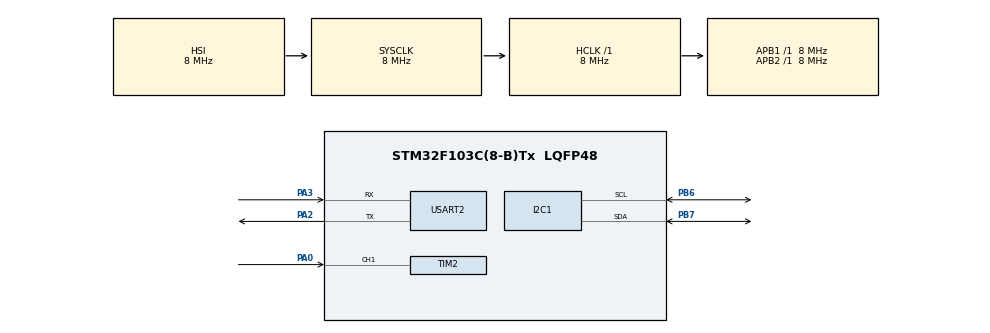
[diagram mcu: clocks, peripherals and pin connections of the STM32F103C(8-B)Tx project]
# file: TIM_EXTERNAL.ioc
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Mcu.Family=STM32F1
Mcu.Name=STM32F103C(8-B)Tx
Mcu.Package=LQFP48
NVIC.PriorityGroup=NVIC_PRIORITYGROUP_4
NVIC.TIM2_IRQn=true\:0\:0\:false\:false\:true\:true\:true\:true
PA0-WKUP.Signal=S_TIM2_CH1_ETR
PA13.Mode=Serial_Wire
PA13.Signal=SYS_JTMS-SWDIO
PA14.Mode=Serial_Wire
PA14.Signal=SYS_JTCK-SWCLK
PA2.Mode=Asynchronous
PA2.Signal=USART2_TX
PA3.Mode=Asynchronous
PA3.Signal=USART2_RX
PB6.Mode=I2C
PB6.Signal=I2C1_SCL
PB7.Mode=I2C
PB7.Signal=I2C1_SDA
ProjectManager.HeapSize=0x200
ProjectManager.StackSize=0x400
ProjectManager.TargetToolchain=STM32CubeIDE
RCC.AHBFreq_Value=8000000
RCC.APB1Freq_Value=8000000
RCC.APB1TimFreq_Value=8000000
RCC.APB2Freq_Value=8000000
RCC.APB2TimFreq_Value=8000000
RCC.HCLKFreq_Value=8000000
RCC.SYSCLKFreq_VALUE=8000000
RCC.USBFreq_Value=8000000
SH.S_TIM2_CH1_ETR.0=TIM2_CH1,TriggerSource_TI1FP1
TIM2.Period=5000-1
TIM2.Prescaler=8000-1
TIM2.Slave_TriggerFilter=15
USART2.VirtualMode=VM_ASYNC
VP_TIM2_VS_ClockSourceINT.Mode=Internal
VP_TIM2_VS_ControllerModeReset.Mode=Reset Mode
board=custom

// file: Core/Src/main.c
/* USER CODE BEGIN Header */
/**
  ******************************************************************************
  * @file           : main.c
  * @brief          : Main program body
  ******************************************************************************
  * @attention
  *
  * Copyright (c) 2024 STMicroelectronics.
  * All rights reserved.
  *
  * This software is licensed under terms that can be found in the LICENSE file
  * in the root directory of this software component.
  * If no LICENSE file comes with this software, it is provided AS-IS.
  *
  ******************************************************************************
  */
/* USER CODE END Header */
#include "main.h"
#include "i2c.h"
#include "tim.h"
#include "usart.h"
#include "gpio.h"

/* USER CODE BEGIN Includes */
#include "oled.h"
#include "stdio.h"
#include "string.h"
/* USER CODE END Includes */

void SystemClock_Config(void);

/* USER CODE BEGIN 0 */
char updataMsg[]="自动重载😊😊😊";
void HAL_TIM_PeriodElapsedCallback(TIM_HandleTypeDef *htim)
{
  if (htim == &htim2)
  {
    HAL_UART_Transmit(&huart2, (uint8_t *)updataMsg, strlen(updataMsg), 100);
  }
}
/* USER CODE END 0 */

int main(void)
{

  /* MCU Configuration--------------------------------------------------------*/

  /* Reset of all peripherals, Initializes the Flash interface and the Systick. */
  HAL_Init();

  /* Configure the system clock */
  SystemClock_Config();

  /* Initialize all configured peripherals */
  MX_GPIO_Init();
  MX_I2C1_Init();
  MX_TIM2_Init();
  MX_USART2_UART_Init();
  /* USER CODE BEGIN 2 */

  HAL_TIM_Base_Start(&htim2);
  int counter = 0;
  char str[20] = "";
  /* USER CODE END 2 */

  /* Infinite loop */
  /* USER CODE BEGIN WHILE */
  while (1)
  {
    //OLED_NewFrame();
    counter = __HAL_TIM_GET_COUNTER(&htim2);
    sprintf(str, "Counter: %d", counter);
    HAL_UART_Transmit(&huart2, (uint8_t *)str, strlen(str), 100);
    //OLED_PrintString(0, 0, str, &font16x16, OLED_COLOR_NORMAL);
    //OLED_ShowFrame();`````````````````````
    HAL_Delay(500);
    /* USER CODE END WHILE */

  }
}

void SystemClock_Config(void)
{
  RCC_OscInitTypeDef RCC_OscInitStruct = {0};
  RCC_ClkInitTypeDef RCC_ClkInitStruct = {0};

  /** Initializes the RCC Oscillators according to the specified parameters
  * in the RCC_OscInitTypeDef structure.
  */
  RCC_OscInitStruct.OscillatorType = RCC_OSCILLATORTYPE_HSI;
  RCC_OscInitStruct.HSIState = RCC_HSI_ON;
  RCC_OscInitStruct.HSICalibrationValue = RCC_HSICALIBRATION_DEFAULT;
  RCC_OscInitStruct.PLL.PLLState = RCC_PLL_NONE;
  if (HAL_RCC_OscConfig(&RCC_OscInitStruct) != HAL_OK)
  {
    Error_Handler();
  }

  /** Initializes the CPU, AHB and APB buses clocks
  */
  RCC_ClkInitStruct.ClockType = RCC_CLOCKTYPE_HCLK|RCC_CLOCKTYPE_SYSCLK
                              |RCC_CLOCKTYPE_PCLK1|RCC_CLOCKTYPE_PCLK2;
  RCC_ClkInitStruct.SYSCLKSource = RCC_SYSCLKSOURCE_HSI;
  RCC_ClkInitStruct.AHBCLKDivider = RCC_SYSCLK_DIV1;
  RCC_ClkInitStruct.APB1CLKDivider = RCC_HCLK_DIV1;
  RCC_ClkInitStruct.APB2CLKDivider = RCC_HCLK_DIV1;

  if (HAL_RCC_ClockConfig(&RCC_ClkInitStruct, FLASH_LATENCY_0) != HAL_OK)
  {
    Error_Handler();
  }
}

void Error_Handler(void)
{
    __disable_irq();
    while (1)
    {
    }
}
